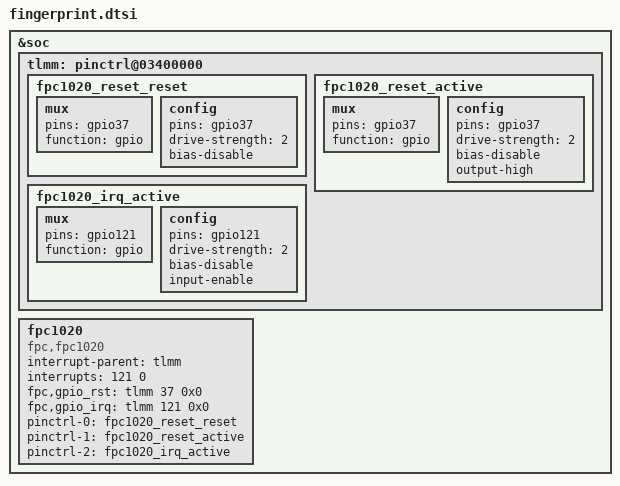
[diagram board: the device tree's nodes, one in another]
&soc {
	tlmm: pinctrl@03400000 {
		fpc1020_reset_reset: fpc1020_reset_reset {
			mux {
				pins = "gpio37";
				function = "gpio";
			};

			config {
				pins = "gpio37";
				drive-strength = <2>;
				bias-disable;
			};
		};

		fpc1020_reset_active: fpc1020_reset_active {
			mux {
				pins = "gpio37";
				function = "gpio";
			};

			config {
				pins = "gpio37";
				drive-strength = <2>;
				bias-disable;
				output-high;
			};
		};

		fpc1020_irq_active: fpc1020_irq_active {
			mux {
				pins = "gpio121";
				function = "gpio";
			};

			config {
				pins = "gpio121";
				drive-strength = <2>;
				bias-disable;
				input-enable;
			};
		};
	};

	fpc1020 {
		compatible = "fpc,fpc1020";
		status = "ok";
		interrupt-parent = <&tlmm>;
		interrupts = <121 0>;
		fpc,gpio_rst = <&tlmm 37 0x0>;
		fpc,gpio_irq = <&tlmm 121 0x0>;

		pinctrl-names = "fpc1020_reset_reset",
				"fpc1020_reset_active",
				"fpc1020_irq_active";

		pinctrl-0 = <&fpc1020_reset_reset>;
		pinctrl-1 = <&fpc1020_reset_active>;
		pinctrl-2 = <&fpc1020_irq_active>;
	};
};
